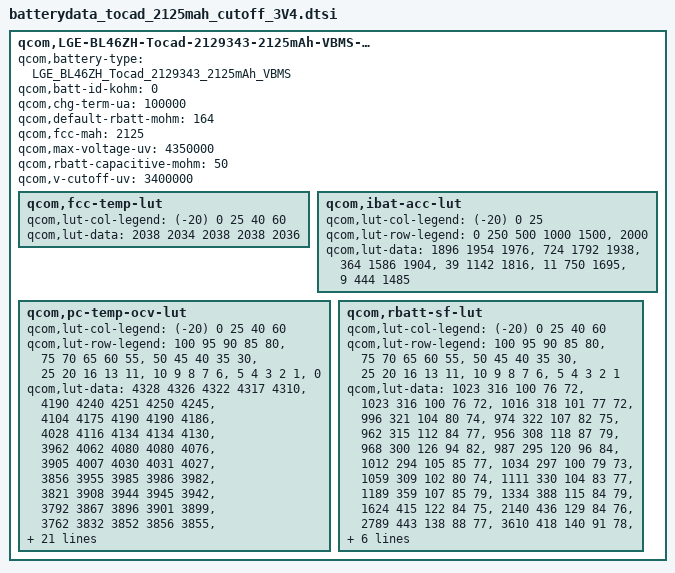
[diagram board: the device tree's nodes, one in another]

qcom,LGE-BL46ZH-Tocad-2129343-2125mAh-VBMS-batterydata {
	qcom,battery-type = "LGE_BL46ZH_Tocad_2129343_2125mAh_VBMS";
	qcom,batt-id-kohm = <0>;
	qcom,chg-term-ua = <100000>;
	qcom,default-rbatt-mohm = <164>;
	qcom,fcc-mah = <2125>;
	qcom,max-voltage-uv = <4350000>;
	qcom,rbatt-capacitive-mohm = <50>;
	qcom,v-cutoff-uv = <3400000>;

	qcom,fcc-temp-lut {
		qcom,lut-col-legend = <(-20) 0 25 40 60>;
		qcom,lut-data = <2038 2034 2038 2038 2036>;
	};

	qcom,ibat-acc-lut {
		qcom,lut-col-legend = <(-20) 0 25>;
		qcom,lut-row-legend = <0 250 500 1000 1500>,
					<2000>;
		qcom,lut-data = <1896 1954 1976>,
				<724 1792 1938>,
				<364 1586 1904>,
				<39 1142 1816>,
				<11 750 1695>,
				<9 444 1485>;
	};

	qcom,pc-temp-ocv-lut {
		qcom,lut-col-legend = <(-20) 0 25 40 60>;
		qcom,lut-row-legend = <100 95 90 85 80>,
					<75 70 65 60 55>,
					<50 45 40 35 30>,
					<25 20 16 13 11>,
					<10 9 8 7 6>,
					<5 4 3 2 1>,
					<0>;
		qcom,lut-data = <4328 4326 4322 4317 4310>,
				<4190 4240 4251 4250 4245>,
				<4104 4175 4190 4190 4186>,
				<4028 4116 4134 4134 4130>,
				<3962 4062 4080 4080 4076>,
				<3905 4007 4030 4031 4027>,
				<3856 3955 3985 3986 3982>,
				<3821 3908 3944 3945 3942>,
				<3792 3867 3896 3901 3899>,
				<3762 3832 3852 3856 3855>,
				<3725 3805 3821 3824 3823>,
				<3684 3786 3800 3802 3802>,
				<3646 3774 3784 3786 3785>,
				<3618 3762 3772 3773 3772>,
				<3594 3748 3765 3762 3755>,
				<3569 3728 3753 3748 3733>,
				<3540 3694 3729 3725 3710>,
				<3510 3652 3698 3698 3686>,
				<3482 3592 3666 3672 3665>,
				<3460 3559 3647 3657 3652>,
				<3448 3545 3639 3650 3645>,
				<3434 3531 3628 3642 3638>,
				<3418 3518 3608 3630 3625>,
				<3400 3505 3588 3616 3612>,
				<3382 3488 3566 3590 3584>,
				<3361 3464 3536 3552 3533>,
				<3334 3424 3484 3492 3464>,
				<3299 3370 3412 3421 3388>,
				<3240 3294 3321 3328 3291>,
				<3140 3184 3202 3196 3148>,
				<3000 3000 3000 3000 3000>;
	};

	qcom,rbatt-sf-lut {
		qcom,lut-col-legend = <(-20) 0 25 40 60>;
		qcom,lut-row-legend = <100 95 90 85 80>,
					<75 70 65 60 55>,
					<50 45 40 35 30>,
					<25 20 16 13 11>,
					<10 9 8 7 6>,
					<5 4 3 2 1>;
		qcom,lut-data = <1023 316 100 76 72>,
				<1023 316 100 76 72>,
				<1016 318 101 77 72>,
				<996 321 104 80 74>,
				<974 322 107 82 75>,
				<962 315 112 84 77>,
				<956 308 118 87 79>,
				<968 300 126 94 82>,
				<987 295 120 96 84>,
				<1012 294 105 85 77>,
				<1034 297 100 79 73>,
				<1059 309 102 80 74>,
				<1111 330 104 83 77>,
				<1189 359 107 85 79>,
				<1334 388 115 84 79>,
				<1624 415 122 84 75>,
				<2140 436 129 84 76>,
				<2789 443 138 88 77>,
				<3610 418 140 91 78>,
				<4626 450 150 96 80>,
				<5232 480 156 100 82>,
				<6008 514 159 104 83>,
				<7216 595 152 111 88>,
				<8537 671 144 113 90>,
				<10662 690 132 103 87>,
				<14697 848 132 96 84>,
				<22191 1257 123 90 85>,
				<39970 2226 127 93 89>,
				<79939 4451 140 100 93>,
				<154147 8902 171 113 117>;
	};
};
